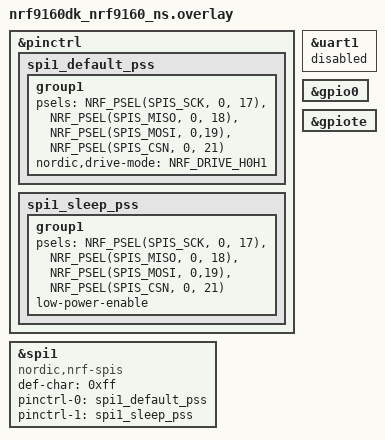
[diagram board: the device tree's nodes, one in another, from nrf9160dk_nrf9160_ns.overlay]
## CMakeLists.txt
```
cmake_minimum_required(VERSION 3.20.0)
find_package(Zephyr REQUIRED HINTS $ENV{ZEPHYR_BASE})

project(nrf91)

target_sources(app PRIVATE src/main.c)
```

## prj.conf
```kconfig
CONFIG_TFM_LOG_LEVEL_SILENCE=y
CONFIG_GPIO=y
CONFIG_SPI=y
CONFIG_SPI_SLAVE=y
CONFIG_SPI_ASYNC=y
CONFIG_SERIAL=y
CONFIG_CONSOLE=y
CONFIG_LOG=y
CONFIG_LOG_PRINTK=n
CONFIG_LOG_OUTPUT=y
```

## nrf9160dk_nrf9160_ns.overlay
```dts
/*    nRF9160 DK GPIO interface between nRF9160 and nRF52840
*
*    This interface can be used for inter-SoC communication on the DK.
*    The connections are as follows:
*
*     | nRF9160 |                            |    nRF52840    |
* SCK |   P0.17 | -- nRF interface line 0 -- | P0.17          | SCK
* MISO|   P0.18 | -- nRF interface line 1 -- | P0.20          | MISO
* MOSI|   P0.19 | -- nRF interface line 2 -- | P0.15          | MOSI
* CS  |   P0.21 | -- nRF interface line 3 -- | P0.22          | CS
*     |   P0.22 | -- nRF interface line 4 -- | P1.04          |
*     |   P0.23 | -- nRF interface line 5 -- | P1.02          |
*     |   COEX0 | -- nRF interface line 6 -- | P1.13          |
*     |   COEX1 | -- nRF interface line 7 -- | P1.11          |
*     |   COEX2 | -- nRF interface line 8 -- | P1.15          |
* RTS |   P0.24 | -- nRF interface line 9 -- | P0.18 (nRESET) | (in v0.14.0 or later) CTS, nRESET is configurable
*/

&pinctrl {
    spi1_default_pss: spi1_default_pss {
        group1 {
            psels = <NRF_PSEL(SPIS_SCK, 0, 17)>,
                <NRF_PSEL(SPIS_MISO, 0, 18)>,
                <NRF_PSEL(SPIS_MOSI, 0,19)>,
                <NRF_PSEL(SPIS_CSN, 0, 21)>;
            nordic,drive-mode = <NRF_DRIVE_H0H1>;
        };
    };

    spi1_sleep_pss: spi1_sleep_pss {
        group1 {
            psels = <NRF_PSEL(SPIS_SCK, 0, 17)>,
            <NRF_PSEL(SPIS_MISO, 0, 18)>,
            <NRF_PSEL(SPIS_MOSI, 0,19)>,
            <NRF_PSEL(SPIS_CSN, 0, 21)>;
            low-power-enable;
        };
    };

};

&uart1 {
    status = "disabled";
};

&gpio0 {
    status = "okay";
};

&gpiote {
    status = "okay";
};

the_spi_slave: &spi1 {
    compatible = "nordic,nrf-spis";
    status = "okay";
    def-char = <0xff>;

    pinctrl-0 = < &spi1_default_pss>;
    pinctrl-1 = < &spi1_sleep_pss>;
    pinctrl-names = "default", "sleep";
    
};
```

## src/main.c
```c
#include <zephyr/kernel.h>
#include <zephyr/device.h>
#include <zephyr/drivers/spi.h>
#include <zephyr/drivers/gpio.h>
#include <zephyr/sys/byteorder.h>
#include <zephyr/logging/log.h>

LOG_MODULE_REGISTER(spi_slave_main, LOG_LEVEL_INF);

#define SLEEP_TIME_MS 1000
#define LED0_NODE DT_ALIAS(led0)
#define THE_SPI_SLAVE DT_NODELABEL(the_spi_slave)



static const struct gpio_dt_spec led = GPIO_DT_SPEC_GET(LED0_NODE, gpios);

static const struct device *const spi_slave_dev = DEVICE_DT_GET(THE_SPI_SLAVE);
static const struct spi_config spi_slave_cfg = {
	.operation = SPI_WORD_SET(8) | SPI_TRANSFER_MSB |
				 SPI_MODE_CPOL | SPI_MODE_CPHA | SPI_OP_MODE_SLAVE,
	.frequency = 125000,
    .slave = 1,
};
static uint8_t slave_tx_buffer[2];
static uint8_t slave_rx_buffer[2];

int spi_slave_init(void) {

	if(!device_is_ready(spi_slave_dev)) {
		LOG_ERR("SPI slave device not ready!\n");
        return -EINVAL;
	}

    return 0;
}

SYS_INIT(spi_slave_init, APPLICATION, CONFIG_KERNEL_INIT_PRIORITY_DEVICE);

const struct spi_buf s_tx_buf = {
    .buf = slave_tx_buffer,
    .len = sizeof(slave_tx_buffer)
};
const struct spi_buf_set s_tx = {
    .buffers = &s_tx_buf,
    .count = 1
};

struct spi_buf s_rx_buf = {
    .buf = slave_rx_buffer,
    .len = sizeof(slave_rx_buffer),
};
const struct spi_buf_set s_rx = {
    .buffers = &s_rx_buf,
    .count = 1
};


int main(void)
{
    int err;
    static uint8_t counter = 0;

    LOG_INF("Hello from slave");

    if (!gpio_is_ready_dt(&led)) {
		return 0;
	}

	err = gpio_pin_configure_dt(&led, GPIO_OUTPUT_ACTIVE);
	if (err < 0) {
		return 0;
	}

    while(1) {
        gpio_pin_toggle_dt(&led);

        slave_tx_buffer[1] = counter++;

        err = spi_read(spi_slave_dev, &spi_slave_cfg,&s_rx);

        if(err >= 0) {
            LOG_INF("SPI Ret Code: %d", err);
            LOG_HEXDUMP_INF(slave_rx_buffer,sizeof(slave_rx_buffer),"Data: ");
            spi_write(spi_slave_dev, &spi_slave_cfg,&s_rx);
        } else {
            LOG_ERR("SPI ERR: %d", err);
        }
    }

    return 0;
}
```
